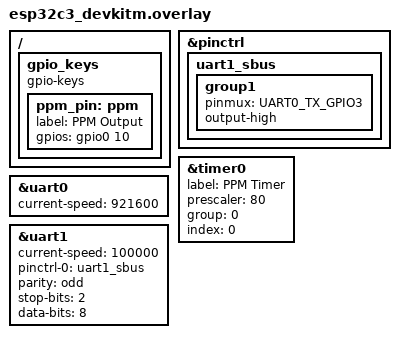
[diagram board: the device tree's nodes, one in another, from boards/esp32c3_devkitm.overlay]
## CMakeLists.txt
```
cmake_minimum_required(VERSION 3.20.0)
set(BOARD esp32c3_devkitm)

find_package(Zephyr REQUIRED HINTS $ENV{ZEPHYR_BASE})
project(HeadTracker_ESP32_receiver)

zephyr_compile_options(-Wno-missing-braces)

FILE(GLOB app_sources src/*.c src/*/*.c)
target_sources(app PRIVATE ${app_sources})
```

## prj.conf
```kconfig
# Sys
CONFIG_POLL=y

# Math
CONFIG_NEWLIB_LIBC=y
CONFIG_NEWLIB_LIBC_NANO=y
CONFIG_NEWLIB_LIBC_FLOAT_PRINTF=y


# Flash
CONFIG_FLASH=y
CONFIG_FLASH_PAGE_LAYOUT=y
CONFIG_SOC_FLASH_ESP32=y
CONFIG_MPU_ALLOW_FLASH_WRITE=y

# Counter
CONFIG_COUNTER=y
CONFIG_COUNTER_TMR_ESP32=y

# Bluetooth
CONFIG_BT=y
CONFIG_BT_DEBUG_LOG=y
CONFIG_BT_SMP=y
CONFIG_BT_CENTRAL=y
CONFIG_BT_GATT_CLIENT=y
CONFIG_BT_CTLR_PHY_2M=y
# CONFIG_BT_CTLR_PHY_CODED=y
CONFIG_BT_L2CAP_TX_MTU=65
CONFIG_BT_GAP_AUTO_UPDATE_CONN_PARAMS=n

# UART / USB
CONFIG_SERIAL=y
CONFIG_DMA=y
CONFIG_DMA_ESP32=y
CONFIG_UART_ASYNC_API=y
CONFIG_UART_INTERRUPT_DRIVEN=y

# Debug
CONFIG_LOG=y
CONFIG_LOG_MODE_IMMEDIATE=y

# # Thread Information
# CONFIG_THREAD_MONITOR=y
CONFIG_DEBUG_THREAD_INFO=y

# Show Thread Information, Use a logging method below (RTT preferred)
CONFIG_THREAD_ANALYZER=y
CONFIG_THREAD_ANALYZER_USE_LOG=y
CONFIG_THREAD_ANALYZER_AUTO=y
CONFIG_THREAD_ANALYZER_AUTO_STACK_SIZE=2048
CONFIG_THREAD_ANALYZER_AUTO_INTERVAL=10

# Disable not used
```

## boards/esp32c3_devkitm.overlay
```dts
/ {
    gpio_keys {
        compatible = "gpio-keys";
        ppm_pin: ppm {
            label = "PPM Output";
            gpios = <&gpio0 10 (GPIO_PULL_DOWN | GPIO_ACTIVE_HIGH)>;
        };
    };
};

&pinctrl{
    uart1_sbus: uart1_sbus
    {
		group1 {
			pinmux = <UART0_TX_GPIO3>;
			output-high;
		};
    };
};

&timer0 {
    status = "ok";
    label = "PPM Timer";
    prescaler = <80>;
    group = <0>;
    index = <0>;
};
/* Flash Layout
 *    Bootloader    0x00000 - 0x10000 (Size 0x10000 64Kb)
 *    Code0         0x10000 - 0x206000 (Size 0x1F6000 2008Kb)
 *    Code1         0x206000 - 0x3FC000 (Size 0x1F6000 2008Kb)
 *    NVM Data      0x3FC000 - 0x400000 (Size 0x4000 16kb)
 */

// &flash0 {
    //     partitions {
        //         compatible = "fixed-partitions";
        //         #address-cells = <1>;
        //         #size-cells = <1>;

        //         boot_partition: partition@0 {
            //             label = "mcuboot";
            //             reg = <0x00000000 0x10000>;
            //             read-only;
        //         };
        //         code0_partition: partition@10000 {
            //             label = "code0";
            //             reg = <0x10000 0x1F6000>;
        //         };
        //         code1_partition: partition@206000 {
            //             label = "code1";
            //             reg = <0x206000 0x1F6000>;
        //         };
        //         datapt_partition: partition@3FC000 {
            //             label = "datapt";
            //             reg = <0x3FC000 0x4000>;
        //         };
    //     };
// };

&uart0 {
    current-speed = <921600>;
};

&uart1 {
    status = "okay";
    current-speed = <100000>;
    pinctrl-0 = <&uart1_sbus>;
    pinctrl-names = "default";
    parity = "odd";
    stop-bits = "2";
    data-bits = <8>;
};
```

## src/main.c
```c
#include <zephyr/kernel.h>
#include <zephyr/device.h>
#include <zephyr/drivers/sensor.h>
#include <zephyr/logging/log.h>

#include "application.h"


int main(void)
{
	printk("HeaderTracker ESP32 by NineDayCC.\nBoard: %s\n", CONFIG_BOARD);

	start();

	return 0;
}
```

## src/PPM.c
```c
#include "PPM.h"

#include <zephyr/device.h>
#include <zephyr/drivers/gpio.h>
#include <zephyr/drivers/counter.h>
#include <zephyr/logging/log.h>
#include <stdio.h>

#include "defines.h"
#include "trackersettings.h"

//------------------------------------------------------------------------------
// Defines
#define DT_TIMER DT_NODELABEL(timer0)
#define DT_PPM_PIN DT_NODELABEL(ppm_pin)
#define ALARM_CHANNEL_ID 0
#define DELAY 100000

//------------------------------------------------------------------------------
// Macro Modules

LOG_MODULE_REGISTER(ppmLog, LOG_LEVEL_DBG);

//------------------------------------------------------------------------------
// Private Values
struct counter_alarm_cfg alarm_cfg;

// Used to read data at once, read with isr disabled
static uint16_t ch_values[16];
static int ch_count;

static uint16_t framesync = PPM_MIN_FRAMESYNC; // Minimum Frame Sync Pulse
static int32_t framelength;                    // Ideal frame length
static uint16_t sync;                          // Sync Pulse Length

// Local data - Only build with interrupts disabled
static uint32_t chsteps[35] = {PPM_MIN_FRAMESYNC, PPM_MIN_SYNC};

// ISR Values - Values from chsteps are copied here on step 0.
// prevent an update from happening mid stream.
static uint32_t isrchsteps[35] = {PPM_MIN_FRAMESYNC, PPM_MIN_SYNC};
static uint16_t chstepcnt = 1;
static uint16_t curstep = 0;
volatile bool buildingdata = false;

/**
 * @brief PPM timer callback function.
 */
static void ppm_counter_interrupt_fn(const struct device *counter_dev,
                                     uint8_t chan_id, uint32_t ticks,
                                     void *user_data)
{
    static const struct gpio_dt_spec ppm_dev = GPIO_DT_SPEC_GET(DT_PPM_PIN, gpios);
    static uint32_t ticks_offset = 0;

    // Reset, don't get stuck in the wrong signal level
    if (curstep == 0)
    {
        // set the first output signal level
        if (isPPMininvert())
            gpio_pin_set_dt(&ppm_dev, 1);
        else
            gpio_pin_set_dt(&ppm_dev, 0);

        // Reset offset for a new ppm period
        ticks_offset = ticks;
    }
    // Not last frame
    else if (curstep < chstepcnt - 1)
    {
        gpio_pin_toggle_dt(&ppm_dev);
    }

    // Setup next capture event value
    // int ticks_over_flag = 0; // test
    struct counter_alarm_cfg *config = user_data;
    config->ticks = ticks_offset + isrchsteps[curstep];

    curstep++;
    // Loop
    if (curstep > chstepcnt)
    {
        if (!buildingdata)
            memcpy(isrchsteps, chsteps, sizeof(isrchsteps[0]) * 35);
        curstep = 0;
    }

    /* Set a new alarm with a double length duration */
    int err = counter_set_channel_alarm(counter_dev, ALARM_CHANNEL_ID,
                                    user_data);
    if (err != 0)
    {
        LOG_ERR("Alarm could not be set");
    }

    // printk("[%s]", now_str());
    // printk("step: %d\n", curstep);
    // printk("ticks: %d\n", now_ticks);
    // printk("over: %d\n", ticks_over_flag);
    // printk("next ticks: %d\n", config->ticks);
    // counter_get_value(counter_dev, &now_ticks);
    // printk("now ticks: %d\n", now_ticks);
    // uint32_t buff = now_ticks;
    // counter_get_value(counter_dev, &now_ticks);
    // printk("elipsed: %d\n", now_ticks - buff);
}

int PPMinit(void)
{
    ch_count = getPPMchcnt();
    sync = getPPMsync();
    framelength = getPPMframe();

    int ret;

    const struct gpio_dt_spec ppm_dev = GPIO_DT_SPEC_GET(DT_PPM_PIN, gpios);
    if (!gpio_is_ready_dt(&ppm_dev))
    {
        LOG_ERR("Error: button device %s is not ready\r\n", ppm_dev.port->name);
        return 0;
    }

    ret = gpio_pin_configure_dt(&ppm_dev, GPIO_OUTPUT);
    if (ret != 0)
    {
        LOG_ERR("Error %d: failed to configure %s pin %d\r\n",
                ret, ppm_dev.port->name, ppm_dev.pin);
        return 0;
    }

    const struct device *const counter_dev = DEVICE_DT_GET(DT_TIMER);
    if (!device_is_ready(counter_dev))
    {
        LOG_ERR("timer not ready.\r\n");
        return 0;
    }

    // Set all channels to center
    for (int i = 0; i < 16; i++)
        ch_values[i] = 1500;

    // Init counter data
    buildChannels();
    // printPPMdata(); // test
    memcpy(isrchsteps, chsteps, sizeof(isrchsteps[0]) * 35);

    // Start ppm counter
    counter_start(counter_dev);

    alarm_cfg.flags = 1;
    alarm_cfg.ticks = counter_us_to_ticks(counter_dev, DELAY);
    alarm_cfg.callback = ppm_counter_interrupt_fn;
    alarm_cfg.user_data = &alarm_cfg;

    // LOG_DBG("alarm freq:%d\n", counter_get_frequency(counter_dev)); // test
    ret = counter_set_channel_alarm(counter_dev, ALARM_CHANNEL_ID,
                                    &alarm_cfg);
    if (-EINVAL == ret)
    {
        LOG_ERR("Alarm settings invalid\r\n");
    }
    else if (-ENOTSUP == ret)
    {
        LOG_ERR("Alarm setting request not supported\r\n");
    }
    else if (ret != 0)
    {
        LOG_ERR("Error\r\n");
    }

    return 0;
}

/**
 * @brief Build timer data for isr to change IO according to Channel data(pwm values).
 */
void buildChannels(void)
{
    buildingdata = true; // Prevent a read happing while this is building

    // Set user defined channel count, frame len, sync pulse
    ch_count = getPPMchcnt();
    sync = getPPMsync();
    framelength = getPPMframe();

    int ch = 0;
    int i;
    uint32_t curtime = framesync;
    chsteps[0] = curtime;
    for (i = 1; i <= ch_count * 2 + 1; i += 2)
    {
        curtime += sync;
        chsteps[i] = curtime;
        curtime += (ch_values[ch++] - sync);
        chsteps[i + 1] = curtime;
    }
    // Add Final Sync
    curtime += sync;
    chsteps[i++] = curtime;
    chstepcnt = i;
    // Now we know how long the train is. Try to make the entire frame == framelength
    // If possible it will add this to the frame sync pulse

    if (framelength >= curtime)
        chsteps[i] = framelength; // Store at end of sequence
    else
        chsteps[i] = 0; // Not possible, no time left
    buildingdata = false;
}

void PpmOut_setChannel(int chan, uint16_t val)
{
    if (chan >= 0 && chan <= ch_count && val >= MIN_PWM &&
        val <= MAX_PWM)
    {
        ch_values[chan] = val;
    }
}

int PpmOut_getChnCount() { return ch_count; }

// test function
void printPPMdata(void)
{
    printf("[%s]", now_str());
    for (uint8_t i = 0; i < sizeof(chsteps) / sizeof(chsteps[0]); i++)
    {
        printf("%d ", chsteps[i]);
    }
    printf("\r\n");
}
```

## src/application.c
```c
#include "application.h"
#include "defines.h"
#include "PPM.h"
#include "bt.h"

void start(void)
{
    PPMinit();
    bt_init();
}

K_THREAD_DEFINE(bt_Thread_id, 1024, bt_Thread, NULL, NULL, NULL, BT_THREAD_PRIO, 0, 5000);

const char *now_str(void)
{
    static char buf[24]; /* ...HH:MM:SS.MMM,UUU */
    uint64_t now = micros64();
    uint16_t us = now % USEC_PER_MSEC;
    uint16_t ms;
    uint8_t s;
    uint8_t min;
    uint32_t h;

    now /= USEC_PER_MSEC;
    ms = now % MSEC_PER_SEC;
    now /= MSEC_PER_SEC;
    s = now % 60U;
    now /= 60U;
    min = now % 60U;
    now /= 60U;
    h = now;

    snprintf(buf, sizeof(buf), "%u:%02u:%02u.%03u,%03u",
             h, min, s, ms, us);
    return buf;
}
```

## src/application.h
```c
#ifndef APPLICATION_H
#define APPLICATION_H

#include <zephyr/kernel.h>

void start(void);
const char *now_str(void);

#endif
```

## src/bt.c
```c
#include "bt.h"

#include <zephyr/kernel.h>
#include <zephyr/types.h>
#include <stddef.h>
#include <errno.h>
#include <stdio.h>

#include <zephyr/bluetooth/bluetooth.h>
#include <zephyr/bluetooth/conn.h>
#include <zephyr/bluetooth/uuid.h>
#include <zephyr/bluetooth/gatt.h>
#include <zephyr/sys/byteorder.h>
#include <zephyr/logging/log.h>

#include "trackersettings.h"
#include "PPM.h"

//------------------------------------------------------------------------------
// Defines
#define BT_HEADTRACKER_UUID_VALUE 0x4EF0
#define BT_PWM_UUID_VALUE 0x4EF1
#define BT_UUID_HEADTRACKER BT_UUID_DECLARE_16(BT_HEADTRACKER_UUID_VALUE)
#define BT_UUID_PWM BT_UUID_DECLARE_16(BT_PWM_UUID_VALUE)

#define BT_MIN_CONN_INTER 10   // Minimum Connection Interval (N * 1.25 ms)
#define BT_MAX_CONN_INTER 10   // Maximum Connection Interval (N * 1.25 ms)
#define BT_CONN_LOST_TIME 100 // Supervision Timeout (N * 10 ms)

//------------------------------------------------------------------------------
// Macro Modules
LOG_MODULE_REGISTER(BtLog, LOG_LEVEL_DBG);

//------------------------------------------------------------------------------
// Private Values

/* BLE connection */
static struct bt_conn *default_conn;

// Service UUID
static struct bt_uuid_16 bt_service_uuid = BT_UUID_INIT_16(
    BT_HEADTRACKER_UUID_VALUE);

// UUID's
struct bt_uuid_16 bt_pwm_uuid = BT_UUID_INIT_16(BT_PWM_UUID_VALUE);

static struct bt_uuid_16 uuid = BT_UUID_INIT_16(0);
static struct bt_gatt_discover_params discover_params;
static struct bt_gatt_subscribe_params subscribe_params;

//--------------------Function Defines--------------------
void printBtData(uint8_t *data);
static void start_scan(void);

static uint8_t notify_func(struct bt_conn *conn,
                           struct bt_gatt_subscribe_params *params,
                           const void *data, uint16_t length)
{
    if (!data)
    {
        LOG_DBG("[UNSUBSCRIBED]");
        params->value_handle = 0U;
        return BT_GATT_ITER_STOP;
    }

    // LOG_DBG("[NOTIFICATION] data %p length %u", data, length);

    uint8_t *channel_data = data;
    for (uint8_t i = 0; i < PpmOut_getChnCount(); i++)
    {
        uint16_t ppmout = (channel_data[i * 2] << 8) | channel_data[i * 2 + 1];
        if (ppmout == 0)
            ppmout = PPM_CENTER;
        // printf("%d  ", ppmout); //test
        PpmOut_setChannel(i, ppmout);
    }
    buildChannels();
    printBtData(channel_data); // test

    return BT_GATT_ITER_CONTINUE;
}

static uint8_t discover_func(struct bt_conn *conn,
                             const struct bt_gatt_attr *attr,
                             struct bt_gatt_discover_params *params)
{
    int err;

    if (!attr)
    {
        LOG_INF("Discover complete");
        (void)memset(params, 0, sizeof(*params));
        return BT_GATT_ITER_STOP;
    }

    if (!bt_uuid_cmp(discover_params.uuid, BT_UUID_HEADTRACKER))
    {
        memcpy(&uuid, BT_UUID_PWM, sizeof(uuid));
        discover_params.uuid = &uuid.uuid;
        discover_params.start_handle = attr->handle + 1;
        discover_params.type = BT_GATT_DISCOVER_CHARACTERISTIC;

        err = bt_gatt_discover(conn, &discover_params);
        if (err)
        {
            LOG_ERR("Discover failed (err %d)", err);
        }
    }
    else if (!bt_uuid_cmp(discover_params.uuid,
                          BT_UUID_PWM))
    {
        memcpy(&uuid, BT_UUID_GATT_CCC, sizeof(uuid));
        discover_params.uuid = &uuid.uuid;
        discover_params.start_handle = attr->handle + 2;
        discover_params.type = BT_GATT_DISCOVER_DESCRIPTOR;
        subscribe_params.value_handle = bt_gatt_attr_value_handle(attr);

        err = bt_gatt_discover(conn, &discover_params);
        if (err)
        {
            LOG_ERR("Discover failed (err %d)", err);
        }
    }
    else
    {
        subscribe_params.notify = notify_func;
        subscribe_params.value = BT_GATT_CCC_NOTIFY;
        subscribe_params.ccc_handle = attr->handle;

        err = bt_gatt_subscribe(conn, &subscribe_params);
        if (err && err != -EALREADY)
        {
            LOG_INF("Subscribe failed (err %d)", err);
        }
        else
        {
            LOG_INF("[SUBSCRIBED]");
        }

        return BT_GATT_ITER_STOP;
    }

    return BT_GATT_ITER_STOP;
}

static bool eir_found(struct bt_data *data, void *user_data)
{
    bt_addr_le_t *addr = user_data;
    int i;

    // LOG_DBG("[AD]: %u data_len %u", data->type, data->data_len);

    switch (data->type)
    {
    case BT_DATA_UUID16_SOME:
    case BT_DATA_UUID16_ALL:
        if (data->data_len % sizeof(uint16_t) != 0U)
        {
            LOG_ERR("AD malformed");
            return true;
        }

        for (i = 0; i < data->data_len; i += sizeof(uint16_t))
        {
            struct bt_le_conn_param *param;
            struct bt_uuid *uuid;
            uint16_t u16_val;
            int err;

            memcpy(&u16_val, &data->data[i], sizeof(u16_val));
            uuid = BT_UUID_DECLARE_16(sys_le16_to_cpu(u16_val));
            if (bt_uuid_cmp(uuid, BT_UUID_HEADTRACKER))
            {
                continue;
            }

            err = bt_le_scan_stop();
            if (err)
            {
                LOG_ERR("Stop LE scan failed (err %d)", err);
                continue;
            }

            param = BT_LE_CONN_PARAM(BT_MIN_CONN_INTER,
                                     BT_MAX_CONN_INTER,
                                     0, BT_CONN_LOST_TIME);
            err = bt_conn_le_create(addr, BT_CONN_LE_CREATE_CONN,
                                    param, &default_conn);
            if (err)
            {
                LOG_ERR("Create conn failed (err %d)", err);
                start_scan();
            }

            return false;
        }
    }

    return true;
}

static void device_found(const bt_addr_le_t *addr, int8_t rssi, uint8_t type,
                         struct net_buf_simple *ad)
{
    char dev[BT_ADDR_LE_STR_LEN];

    bt_addr_le_to_str(addr, dev, sizeof(dev));
    // LOG_DBG("[DEVICE]: %s, AD evt type %u, AD data len %u, RSSI %i",
    //    dev, type, ad->len, rssi);

    /* We're only interested in connectable events */
    if (type == BT_GAP_ADV_TYPE_ADV_IND ||
        type == BT_GAP_ADV_TYPE_ADV_DIRECT_IND)
    {
        bt_data_parse(ad, eir_found, (void *)addr);
    }
}

static void start_scan(void)
{
    int err;

    /* Use active scanning and disable duplicate filtering to handle any
     * devices that might update their advertising data at runtime. */
    struct bt_le_scan_param scan_param = {
        .type = BT_LE_SCAN_TYPE_ACTIVE,
        .options = BT_LE_SCAN_OPT_NONE,
        .interval = BT_GAP_SCAN_FAST_INTERVAL,
        .window = BT_GAP_SCAN_FAST_WINDOW,
    };

    err = bt_le_scan_start(&scan_param, device_found);
    if (err)
    {
        LOG_ERR("Scanning failed to start (err %d)", err);
        return;
    }

    LOG_INF("Scanning successfully started");
}

static void connected(struct bt_conn *conn, uint8_t conn_err)
{
    char addr[BT_ADDR_LE_STR_LEN];
    int err;

    bt_addr_le_to_str(bt_conn_get_dst(conn), addr, sizeof(addr));

    if (conn_err)
    {
        LOG_ERR("Failed to connect to %s (%u)", addr, conn_err);

        bt_conn_unref(default_conn);
        default_conn = NULL;

        start_scan();
        return;
    }

    LOG_INF("Connected: %s", addr);

    struct bt_conn_info info;
    bt_conn_get_info(default_conn, &info);

    LOG_INF("BT Connection Params Int:%d Lat:%d Timeout:%d", info.le.interval, info.le.latency,
            info.le.timeout);
    // LOG_INF("Requesting coded PHY - %s",
    // bt_conn_le_phy_update(pararmtconn, &phy_params) ? "FAILED" : "Success");

    if (conn == default_conn)
    {
        memcpy(&uuid, BT_UUID_HEADTRACKER, sizeof(uuid));
        discover_params.uuid = &uuid.uuid;
        discover_params.func = discover_func;
        discover_params.start_handle = BT_ATT_FIRST_ATTRIBUTE_HANDLE;
        discover_params.end_handle = BT_ATT_LAST_ATTRIBUTE_HANDLE;
        discover_params.type = BT_GATT_DISCOVER_PRIMARY;

        err = bt_gatt_discover(default_conn, &discover_params);
        if (err)
        {
            LOG_ERR("Discover failed(err %d)", err);
            return;
        }
    }
}

static void disconnected(struct bt_conn *conn, uint8_t reason)
{
    char addr[BT_ADDR_LE_STR_LEN];

    bt_addr_le_to_str(bt_conn_get_dst(conn), addr, sizeof(addr));

    LOG_INF("Disconnected: %s (reason 0x%02x)", addr, reason);

    if (default_conn != conn)
    {
        return;
    }

    bt_conn_unref(default_conn);
    default_conn = NULL;

    start_scan();
}

BT_CONN_CB_DEFINE(conn_callbacks) = {
    .connected = connected,
    .disconnected = disconnected,
};

void bt_init()
{
    int err = bt_enable(NULL);
    if (err)
    {
        LOG_ERR("bt_enable failed (err %d)", err);
        return;
    }

    start_scan();
    LOG_INF("Bluetooth initialized");
}

void bt_Thread()
{
    int64_t usduration = 0;
    while (1)
    {

        usduration = micros64();

        // struct bt_conn_info info;
        // bt_conn_get_info(default_conn, &info);

        // LOG_INF("BT Connection Params Int:%d Lat:%d Timeout:%d", info.le.interval, info.le.latency,
        //         info.le.timeout);

        // Adjust sleep for a more accurate period
        usduration = micros64() - usduration;
        if (BT_PERIOD - usduration <
            BT_PERIOD * 0.7)
        { // Took a long time. Will crash if sleep is too short
            k_usleep(BT_PERIOD);
        }
        else
        {
            k_usleep(BT_PERIOD - usduration);
        }
    }
}

void printBtData(uint8_t *data)
{
    uint16_t u16_val;
    printf("[%s]", now_str());
    for (uint8_t i = 0; i < BT_CHANNELS; i++)
    {
        u16_val = (data[i * 2] << 8) | data[i * 2 + 1];
        printf("%d  ", u16_val);
    }
    printf("\r\n");
}
```

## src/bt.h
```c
#ifndef BT_H
#define BT_H

#include <zephyr/kernel.h>
#include "defines.h"


void bt_Thread();
void bt_init();


#endif
```

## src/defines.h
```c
#ifndef DEFINES_H
#define DEFINES_H

// Math
#ifndef M_PI
#define M_PI (3.14159265358979323846)
#endif
#define M_G 9.806650

#define SAMPLE_RATE (int)(1000000 / IMU_PERIOD) // IMU sample rate, replace this with actual sample rate(Hz)

// Thread Periods
#define IO_PERIOD 25 // (ms) IO Period (button reading)
#define BT_PERIOD 7500        // (us) Bluetooth update rate
// #define SERIAL_PERIOD 30       // (ms) Serial processing
// #define DATA_PERIOD 2          // Multiplier of Serial Period (Live Data Transmission Speed)
#define IMU_PERIOD 5000             // (us) Sensor Reads
#define CALCULATE_PERIOD IMU_PERIOD // (us) Channel Calculations
// #define UART_PERIOD 4000       // (us) Update rate of UART
// #define PWM_FREQUENCY 50       // (ms) PWM Period
// #define PAUSE_BEFORE_FLASH 60  // (ms) Time to pause all threads before Flash writing

// Thread Priority Definitions
#define PRIORITY_LOW 12
#define PRIORITY_MED 9
#define PRIORITY_HIGH 6
#define PRIORITY_RT 3

// Thread Periods, Negative values mean cannot be pre-empted
#define IO_THREAD_PRIO PRIORITY_LOW
// #define SERIAL_THREAD_PRIO PRIORITY_LOW
// #define DATA_THREAD_PRIO PRIORITY_LOW
#define BT_THREAD_PRIO -15
#define IMU_THREAD_PRIO PRIORITY_MED
#define CALCULATE_THREAD_PRIO PRIORITY_HIGH
// #define UARTRX_THREAD_PRIO PRIORITY_LOW - 2
// #define UARTTX_THREAD_PRIO PRIORITY_HIGH

#define millis64() k_cyc_to_ms_floor64(k_cycle_get_64())
#define micros64() k_cyc_to_us_floor64(k_cycle_get_64())

#endif
```

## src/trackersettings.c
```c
#include "trackersettings.h"

#include <zephyr/kernel.h>

TrackerSettings trkset = {
    .v.rollReverse = 0, // Roll direction reversed. Y:1 N:0
    .v.tiltReverse = 0, // Tilt direction reversed. Y:1 N:0
    .v.panReverse = 0,  // Pan direction reversed. Y:1 N:0

    .v.useMagn = 0,     // Use Magnetometer. Y:1 N:0
    .v.useBlutooth = 0, // Open Blutooth. Y:1 N:0

    .v.rollEn = 1, // Enable roll ppm output
    .v.tiltEn = 1, // Enable tile ppm output
    .v.panEn = 1,  // Enable pan ppm output

    .v.rollMax = DEF_MAX_PWM, // pwm max
    .v.rollMin = DEF_MIN_PWM, // pwm min
    .v.tiltMax = DEF_MAX_PWM, // pwm max
    .v.tiltMin = DEF_MIN_PWM, // pwm min
    .v.panMax = DEF_MAX_PWM,  // pwm max
    .v.panMin = DEF_MIN_PWM,  // pwm min

    .v.rollGain = 14.3, // 1000/servo max rang, 11 - 90degress, 14.3 - 70d
    .v.tiltGain = 14.3, // 1000/servo max rang, 11 - 90degress, 14.3 - 70d
    .v.panGain = 8.3, // 1000/servo max rang, 5.5 - 180degress, 8.3 -120d

    .v.rollCnt = PPM_CENTER, // Roll pwm center
    .v.tiltCnt = PPM_CENTER, // Tilt pwm center
    .v.panCnt = PPM_CENTER,  // Pan pwm center

    .v.rollChl = 6, // Roll channel
    .v.tiltChl = 7, // Tilt channel
    .v.panChl = 8,  // Pan channel

    .v.accOffset = {0.0f, 0.0f, 0.0f}, // in g
    .v.gyrOffset = {0.1192821793f, 0.512078988f, 0.4421201354f}, // in degress
    // .v.gyrOffset = {0.0f, 0.0f, 0.0f}, // in degress

    .v.ppmininvert = 1,
    .v.ppmframe = 22000, // PPM Frame Length (us)
    .v.ppmsync = 300,    // PPM Sync Pulse Length (us)
    .v.ppmchcnt = 8,     // PPM channels to output

    .v.btmode = 1,      //0:off 1:output mode
};
```

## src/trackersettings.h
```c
#ifndef TRACKERSETTINGS_H
#define TRACKERSETTINGS_H

#include <zephyr/kernel.h>

typedef union
{
    uint8_t array[80];

    struct __attribute__((packed))
    {
        uint8_t rollReverse : 1; // Roll direction reversed. Y:1 N:0
        uint8_t tiltReverse : 1; // Tilt direction reversed. Y:1 N:0
        uint8_t panReverse : 1;  // Pan direction reversed. Y:1 N:0

        uint8_t useMagn : 1;     // Use Magnetometer. Y:1 N:0
        uint8_t useBlutooth : 1; // Open Blutooth. Y:1 N:0

        uint8_t rollEn : 1; // Enable roll ppm output
        uint8_t tiltEn : 1; // Enable tilt ppm output
        uint8_t panEn : 1;  // Enable pan ppm output

        uint16_t rollMax; // pwm max
        uint16_t rollMin; // pwm min
        uint16_t tiltMax; // pwm max
        uint16_t tiltMin; // pwm min
        uint16_t panMax;  // pwm max
        uint16_t panMin;  // pwm min

        float rollGain;
        float tiltGain;
        float panGain;

        uint16_t rollCnt; // Roll pwm center
        uint16_t tiltCnt; // tilt pwm center
        uint16_t panCnt;  // pan pwm center

        uint8_t rollChl; // Roll channel
        uint8_t tiltChl; // Tilt channel
        uint8_t panChl;  // Pan channel

        float accOffset[3]; // accelerometerOffset in g, X Y Z
        float gyrOffset[3]; // gyroscopeOffset in degrees/s, X Y Z

        uint8_t ppmininvert : 1;
        uint8_t reserved : 7;

        uint16_t ppmframe;  // PPM Frame Length (us)
        uint16_t ppmsync;   // PPM Sync Pulse Length (us)
        uint8_t ppmchcnt;   // PPM channels to output

        uint8_t btmode; // Bluetooth mode 0:off 1:output mode
    } v; // Value
} TrackerSettings;

extern TrackerSettings trkset;

inline bool isUsingMagn(void) { return trkset.v.useMagn; }
inline bool isUsingBlutooth(void) { return trkset.v.useBlutooth; }
inline bool isRollReversed(void) { return trkset.v.rollReverse; }
inline bool isTiltReversed(void) { return trkset.v.tiltReverse; }
inline bool isPanReversed(void) { return trkset.v.panReverse; }
inline bool isRollEn(void) { return trkset.v.rollEn; }
inline bool isTiltEn(void) { return trkset.v.tiltEn; }
inline bool isPanEn(void) { return trkset.v.panEn; }

inline uint16_t getRollMax(void) { return trkset.v.rollMax; }
inline uint16_t getRollMin(void) { return trkset.v.rollMin; }
inline uint16_t getTiltMax(void) { return trkset.v.tiltMax; }
inline uint16_t getTiltMin(void) { return trkset.v.tiltMin; }
inline uint16_t getPanMax(void) { return trkset.v.panMax; }
inline uint16_t getPanMin(void) { return trkset.v.panMin; }

inline float getRollGain(void) { return trkset.v.rollGain; }
inline float getTiltGain(void) { return trkset.v.tiltGain; }
inline float getPanGain(void) { return trkset.v.panGain; }

inline uint16_t getRollCnt(void) { return trkset.v.rollCnt; }
inline uint16_t getTiltCnt(void) { return trkset.v.tiltCnt; }
inline uint16_t getPanCnt(void) { return trkset.v.panCnt; }

inline uint8_t getRollChl(void) { return trkset.v.rollChl; }
inline uint8_t getTiltChl(void) { return trkset.v.tiltChl; }
inline uint8_t getPanChl(void) { return trkset.v.panChl; }

inline float *getAccOffset(void) { return trkset.v.accOffset; }
inline float *getGyrOffset(void) { return trkset.v.gyrOffset; }

inline bool isPPMininvert(void) { return trkset.v.ppmininvert; }
inline uint16_t getPPMframe(void) { return trkset.v.ppmframe; }
inline uint16_t getPPMsync(void) { return trkset.v.ppmsync; }
inline uint8_t getPPMchcnt(void) { return trkset.v.ppmchcnt; }

inline uint8_t getBtMode(void) { return trkset.v.btmode; }

#define FLOAT_MIN -1000000
#define FLOAT_MAX 1000000
#define MIN_PWM 980
#define MAX_PWM 2020
#define DEF_MIN_PWM 988
#define DEF_MAX_PWM 2012
#define PPM_CENTER 1500
#define MIN_GAIN 0.01
#define MAX_GAIN 35
#define MINMAX_RNG 487
#define MIN_TO_CENTER 25
#define MIN_CNT (((MAX_PWM - MIN_PWM) / 2) + MIN_PWM - MINMAX_RNG)
#define MAX_CNT (((MAX_PWM - MIN_PWM) / 2) + MIN_PWM + MINMAX_RNG)
#define BT_CHANNELS 8
#define MAX_CHANNELS 16
#define AUX_FUNCTIONS 7
#define SBUS_CENTER 992
#define SBUS_SCALE 1.6
#define RESET_ON_TILT_TIME 1.5
#define RESET_ON_TILT_AFTER 1
#define RECENTER_PULSE_DURATION 0.5
#define UART_ACTIVE_TIME 0.1
#define PPM_MIN_FRAMESYNC 3000
#define PPM_MIN_SYNC 500
#define PPM_MIN_FRAME 6666
#define PPM_MAX_FRAME 40000
#define UART_MODE_OFF 0
#define UART_MODE_SBUS 1
#define UART_MODE_CRSFIN 2
#define UART_MODE_CRSFOUT 3

#endif
```
